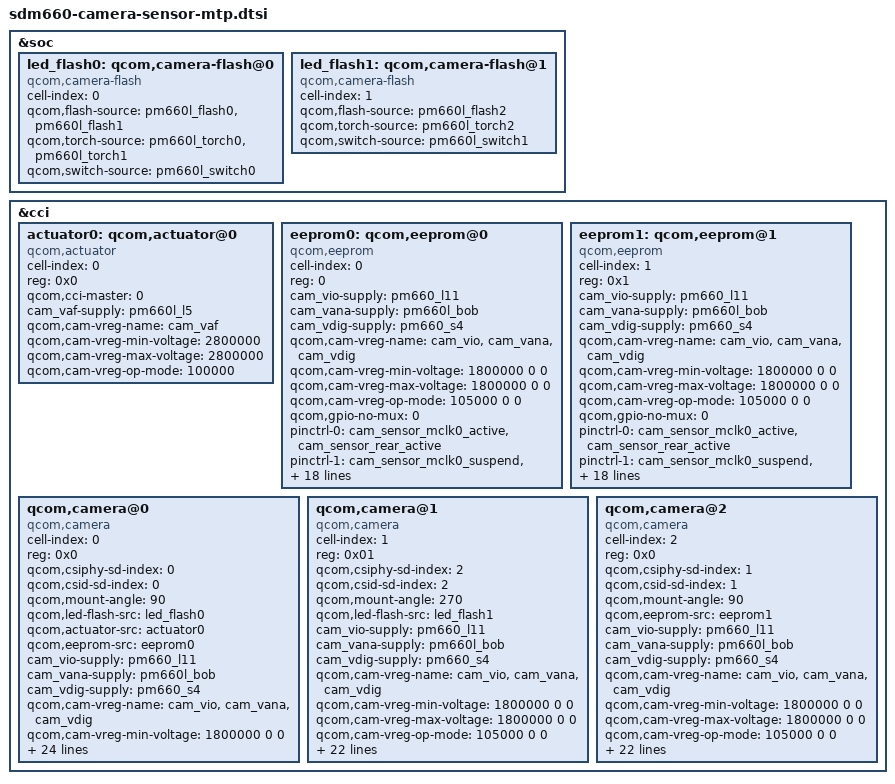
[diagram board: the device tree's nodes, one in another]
/*
 * Copyright (c) 2016-2017, The Linux Foundation. All rights reserved.
 *
 * This program is free software; you can redistribute it and/or modify
 * it under the terms of the GNU General Public License version 2 and
 * only version 2 as published by the Free Software Foundation.
 *
 * This program is distributed in the hope that it will be useful,
 * but WITHOUT ANY WARRANTY; without even the implied warranty of
 * MERCHANTABILITY or FITNESS FOR A PARTICULAR PURPOSE.  See the
 * GNU General Public License for more details.
 */

&soc {
	led_flash0: qcom,camera-flash@0 {
		cell-index = <0>;
		compatible = "qcom,camera-flash";
		qcom,flash-source = <&pm660l_flash0 &pm660l_flash1>;
		qcom,torch-source = <&pm660l_torch0 &pm660l_torch1>;
		qcom,switch-source = <&pm660l_switch0>;
		status = "ok";
	};

	led_flash1: qcom,camera-flash@1 {
		cell-index = <1>;
		compatible = "qcom,camera-flash";
		qcom,flash-source = <&pm660l_flash2>;
		qcom,torch-source = <&pm660l_torch2>;
		qcom,switch-source = <&pm660l_switch1>;
		status = "ok";
	};
};

&cci {
	actuator0: qcom,actuator@0 {
		cell-index = <0>;
		reg = <0x0>;
		compatible = "qcom,actuator";
		qcom,cci-master = <0>;
		cam_vaf-supply = <&pm660l_l5>;
		qcom,cam-vreg-name = "cam_vaf";
		qcom,cam-vreg-min-voltage = <2800000>;
		qcom,cam-vreg-max-voltage = <2800000>;
		qcom,cam-vreg-op-mode = <100000>;
	};

	eeprom0: qcom,eeprom@0 {
		cell-index = <0>;
		reg = <0>;
		compatible = "qcom,eeprom";
		cam_vio-supply = <&pm660_l11>;
		cam_vana-supply = <&pm660l_bob>;
		cam_vdig-supply = <&pm660_s4>;
		qcom,cam-vreg-name = "cam_vio", "cam_vana", "cam_vdig";
		qcom,cam-vreg-min-voltage = <1800000 0 0>;
		qcom,cam-vreg-max-voltage = <1800000 0 0>;
		qcom,cam-vreg-op-mode = <105000 0 0>;
		qcom,gpio-no-mux = <0>;
		pinctrl-names = "cam_default", "cam_suspend";
		pinctrl-0 = <&cam_sensor_mclk0_active
				 &cam_sensor_rear_active>;
		pinctrl-1 = <&cam_sensor_mclk0_suspend
				 &cam_sensor_rear_suspend>;
		gpios = <&tlmm 32 0>,
			<&tlmm 46 0>,//reset
			<&tlmm 44 0>,//standby
			<&tlmm 80 0>,//vana
			<&tlmm 77 0>;//vdig
		qcom,gpio-reset = <1>;
		qcom,gpio-standby = <2>;
		qcom,gpio-vana = <3>;
		qcom,gpio-vdig = <4>;
		qcom,gpio-req-tbl-num = <0 1 2 3 4>;
		qcom,gpio-req-tbl-flags = <1 0 0 0 0>;
		qcom,gpio-req-tbl-label = "CAMIF_MCLK0",
					  "CAM_RESET0",
					  "CAM_STANDBY0",
					  "CAM_VANA0",
				      "CAM_VDIG0";
		qcom,sensor-position = <0>;
		qcom,sensor-mode = <0>;
		qcom,cci-master = <0>;
		status = "ok";
		clocks = <&clock_mmss MCLK0_CLK_SRC>,
			<&clock_mmss MMSS_CAMSS_MCLK0_CLK>;
		clock-names = "cam_src_clk", "cam_clk";
		qcom,clock-rates = <24000000 0>;
	};

	eeprom1: qcom,eeprom@1 {
		cell-index = <1>;
		reg = <0x1>;
		compatible = "qcom,eeprom";
		cam_vio-supply = <&pm660_l11>;
		cam_vana-supply = <&pm660l_bob>;
		cam_vdig-supply = <&pm660_s4>;
		qcom,cam-vreg-name = "cam_vio", "cam_vana", "cam_vdig";
		qcom,cam-vreg-min-voltage = <1800000 0 0>;
		qcom,cam-vreg-max-voltage = <1800000 0 0>;
		qcom,cam-vreg-op-mode = <105000 0 0>;
		qcom,gpio-no-mux = <0>;
		pinctrl-names = "cam_default", "cam_suspend";
		pinctrl-0 = <&cam_sensor_mclk0_active
				 &cam_sensor_rear_active>;
		pinctrl-1 = <&cam_sensor_mclk0_suspend
				 &cam_sensor_rear_suspend>;
		gpios = <&tlmm 32 0>,
			<&tlmm 46 0>,//reset
			<&tlmm 44 0>,//standby
			<&tlmm 80 0>,//vana
			<&tlmm 77 0>;//vdig
		qcom,gpio-reset = <1>;
		qcom,gpio-standby = <2>;
		qcom,gpio-vana = <3>;
		qcom,gpio-vdig = <4>;
		qcom,gpio-req-tbl-num = <0 1 2 3 4>;
		qcom,gpio-req-tbl-flags = <1 0 0 0 0>;
		qcom,gpio-req-tbl-label = "CAMIF_MCLK0",
					  "CAM_RESET0",
					  "CAM_STANDBY0",
					  "CAM_VANA0",
				      "CAM_VDIG0";
		qcom,sensor-position = <0>;
		qcom,sensor-mode = <0>;
		qcom,cci-master = <0>;
		status = "ok";
		clocks = <&clock_mmss MCLK0_CLK_SRC>,
			<&clock_mmss MMSS_CAMSS_MCLK0_CLK>;
		clock-names = "cam_src_clk", "cam_clk";
		qcom,clock-rates = <24000000 0>;
	};

//rear master camera ---start
	qcom,camera@0 {
		cell-index = <0>;
		compatible = "qcom,camera";
		reg = <0x0>;
		qcom,csiphy-sd-index = <0>;
		qcom,csid-sd-index = <0>;
		qcom,mount-angle = <90>;
		qcom,led-flash-src = <&led_flash0>;
		qcom,actuator-src = <&actuator0>;
		qcom,eeprom-src = <&eeprom0>;
		cam_vio-supply = <&pm660_l11>;
		cam_vana-supply = <&pm660l_bob>;
		cam_vdig-supply = <&pm660_s4>;
		qcom,cam-vreg-name = "cam_vio", "cam_vana", "cam_vdig";
		qcom,cam-vreg-min-voltage = <1800000 0 0>;
		qcom,cam-vreg-max-voltage = <1800000 0 0>;
		qcom,cam-vreg-op-mode = <105000 0 0>;
		qcom,gpio-no-mux = <0>;
		pinctrl-names = "cam_default", "cam_suspend";
		pinctrl-0 = <&cam_sensor_mclk0_active
				 &cam_sensor_rear_active>;
		pinctrl-1 = <&cam_sensor_mclk0_suspend
				 &cam_sensor_rear_suspend>;
		gpios = <&tlmm 32 0>,
			<&tlmm 46 0>,//reset
			<&tlmm 44 0>,//standby
			<&tlmm 80 0>,//vana
			<&tlmm 77 0>;//vdig
		qcom,gpio-reset = <1>;
		qcom,gpio-standby = <2>;
		qcom,gpio-vana = <3>;
		qcom,gpio-vdig = <4>;
		qcom,gpio-req-tbl-num = <0 1 2 3 4>;
		qcom,gpio-req-tbl-flags = <1 0 0 0 0>;
		qcom,gpio-req-tbl-label = "CAMIF_MCLK0",
					  "CAM_RESET0",
					  "CAM_STANDBY0",
					  "CAM_VANA0",
				      "CAM_VDIG0";
		qcom,sensor-position = <0>;
		qcom,sensor-mode = <0>;
		qcom,cci-master = <0>;
		status = "ok";
		clocks = <&clock_mmss MCLK0_CLK_SRC>,
			<&clock_mmss MMSS_CAMSS_MCLK0_CLK>;
		clock-names = "cam_src_clk", "cam_clk";
		qcom,clock-rates = <24000000 0>;
	};
//rear master camera ---end

//front camera ---start
	qcom,camera@1 {
		cell-index = <1>;
		compatible = "qcom,camera";
		reg = <0x01>;
		qcom,csiphy-sd-index = <2>;
		qcom,csid-sd-index = <2>;
		qcom,mount-angle = <270>;
		qcom,led-flash-src = <&led_flash1>;
		cam_vio-supply = <&pm660_l11>;
		cam_vana-supply = <&pm660l_bob>;
		cam_vdig-supply = <&pm660_s4>;
		qcom,cam-vreg-name = "cam_vio", "cam_vana", "cam_vdig";
		qcom,cam-vreg-min-voltage = <1800000 0 0>;
		qcom,cam-vreg-max-voltage = <1800000 0 0>;
		qcom,cam-vreg-op-mode = <105000 0 0>;
		qcom,gpio-no-mux = <0>;
		pinctrl-names = "cam_default", "cam_suspend";
		pinctrl-0 = <&cam_sensor_mclk1_active
				 &cam_sensor_front_active>;
		pinctrl-1 = <&cam_sensor_mclk1_suspend
				 &cam_sensor_front_suspend>;
		gpios = <&tlmm 33 0>,
			<&tlmm 47 0>,//reset
			<&tlmm 48 0>,//standby
			<&tlmm 12 0>,//vana
			<&tlmm 51 0>;//vdig
		qcom,gpio-reset = <1>;
		qcom,gpio-standby = <2>;
		qcom,gpio-vana = <3>;
		qcom,gpio-vdig = <4>;
		qcom,gpio-req-tbl-num = <0 1 2 3 4>;
		qcom,gpio-req-tbl-flags = <1 0 0 0 0>;
		qcom,gpio-req-tbl-label = "CAMIF_MCLK2",
					"CAM_RESET2",
					"CAM_STANDBY2",
					"CAM_VANA2",
				    "CAM_VDIG2";
		qcom,sensor-position = <1>;
		qcom,sensor-mode = <0>;
		qcom,cci-master = <1>;
		status = "ok";
		clocks = <&clock_mmss MCLK1_CLK_SRC>,
			<&clock_mmss MMSS_CAMSS_MCLK1_CLK>;
		clock-names = "cam_src_clk", "cam_clk";
		qcom,clock-rates = <24000000 0>;
	};
//front camera ---end

//rear slave camera ---start
	qcom,camera@2 {
		cell-index = <2>;
		compatible = "qcom,camera";
		reg = <0x0>;
		qcom,csiphy-sd-index = <1>;
		qcom,csid-sd-index = <1>;
		qcom,mount-angle = <90>;
		//qcom,led-flash-src = <&led_flash0>;
		qcom,eeprom-src = <&eeprom1>;
		cam_vio-supply = <&pm660_l11>;
		cam_vana-supply = <&pm660l_bob>;
		cam_vdig-supply = <&pm660_s4>;
		qcom,cam-vreg-name = "cam_vio", "cam_vana", "cam_vdig";
		qcom,cam-vreg-min-voltage = <1800000 0 0>;
		qcom,cam-vreg-max-voltage = <1800000 0 0>;
		qcom,cam-vreg-op-mode = <105000 0 0>;
		qcom,gpio-no-mux = <0>;
		pinctrl-names = "cam_default", "cam_suspend";
		pinctrl-0 = <&cam_sensor_mclk3_active
				 &cam_sensor_rear_slave_active>;
		pinctrl-1 = <&cam_sensor_mclk3_suspend
				 &cam_sensor_rear_slave_suspend>;
		gpios = <&tlmm 35 0>,
			<&tlmm 52 0>,//reset
			<&tlmm 49 0>,//standby
			<&tlmm 80 0>,//vana
			<&tlmm 13 0>;//vdig
		qcom,gpio-reset = <1>;
		qcom,gpio-standby = <2>;
		qcom,gpio-vana = <3>;
		qcom,gpio-vdig = <4>;
		qcom,gpio-req-tbl-num = <0 1 2 3 4>;
		qcom,gpio-req-tbl-flags = <1 0 0 0 0>;
		qcom,gpio-req-tbl-label = "CAMIF_MCLK3",
					"CAM_RESET3",
					"CAM_STANDBY3",
					"CAM_VANA3",
					"CAM_VDIG3";
		qcom,sensor-position = <0>;
		qcom,sensor-mode = <0>;
		qcom,cci-master = <1>;
		status = "ok";
		clocks = <&clock_mmss MCLK3_CLK_SRC>,
				<&clock_mmss MMSS_CAMSS_MCLK3_CLK>;
		clock-names = "cam_src_clk", "cam_clk";
		qcom,clock-rates = <24000000 0>;
	};
//rear slave camera ---end

};
